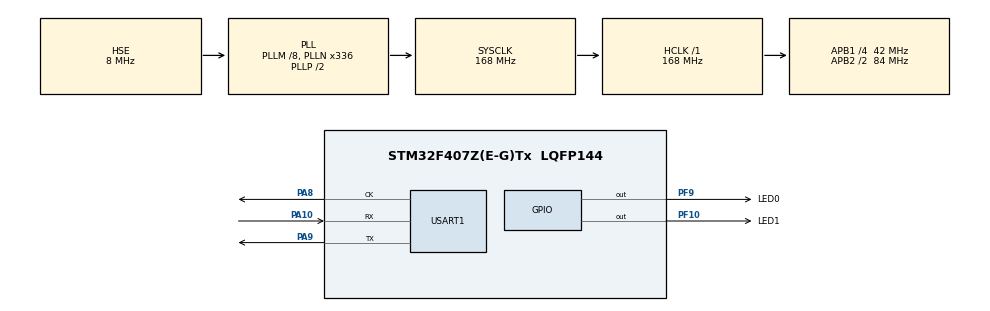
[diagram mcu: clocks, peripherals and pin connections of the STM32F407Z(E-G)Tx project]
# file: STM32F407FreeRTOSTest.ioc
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FREERTOS.Tasks01=LED0_Task,0,128,LED0,Default,NULL,Dynamic,NULL,NULL;LED1_Task,-3,128,LED1,Default,NULL,Dynamic,NULL,NULL
Mcu.Family=STM32F4
Mcu.Name=STM32F407Z(E-G)Tx
Mcu.Package=LQFP144
NVIC.PriorityGroup=NVIC_PRIORITYGROUP_4
NVIC.TIM6_DAC_IRQn=true\:15\:0\:false\:false\:true\:false\:false\:true
NVIC.TimeBase=TIM6_DAC_IRQn
NVIC.TimeBaseIP=TIM6
NVIC.USART1_IRQn=true\:5\:0\:false\:false\:true\:true\:true\:true
PA10.Mode=Synchronous
PA10.Signal=USART1_RX
PA13.Mode=Serial_Wire
PA13.Signal=SYS_JTMS-SWDIO
PA14.Mode=Serial_Wire
PA14.Signal=SYS_JTCK-SWCLK
PA8.Mode=Synchronous
PA8.Signal=USART1_CK
PA9.Mode=Synchronous
PA9.Signal=USART1_TX
PC14-OSC32_IN.Mode=LSE-External-Oscillator
PC14-OSC32_IN.Signal=RCC_OSC32_IN
PC15-OSC32_OUT.Mode=LSE-External-Oscillator
PC15-OSC32_OUT.Signal=RCC_OSC32_OUT
PF10.GPIO_Label=LED1
PF10.GPIO_Speed=GPIO_SPEED_FREQ_LOW
PF10.Signal=GPIO_Output
PF9.GPIO_Label=LED0
PF9.GPIO_Speed=GPIO_SPEED_FREQ_LOW
PF9.Signal=GPIO_Output
PH0-OSC_IN.Mode=HSE-External-Oscillator
PH0-OSC_IN.Signal=RCC_OSC_IN
PH1-OSC_OUT.Mode=HSE-External-Oscillator
PH1-OSC_OUT.Signal=RCC_OSC_OUT
ProjectManager.HeapSize=0x200
ProjectManager.StackSize=0x400
ProjectManager.TargetToolchain=MDK-ARM V5.32
RCC.48MHZClocksFreq_Value=84000000
RCC.AHBFreq_Value=168000000
RCC.APB1CLKDivider=RCC_HCLK_DIV4
RCC.APB1Freq_Value=42000000
RCC.APB1TimFreq_Value=84000000
RCC.APB2CLKDivider=RCC_HCLK_DIV2
RCC.APB2Freq_Value=84000000
RCC.APB2TimFreq_Value=168000000
RCC.CortexFreq_Value=168000000
RCC.EnbaleCSS=true
RCC.HCLKFreq_Value=168000000
RCC.HSE_VALUE=8000000
RCC.HSI_VALUE=16000000
RCC.PLLM=8
RCC.PLLN=336
RCC.PLLSourceVirtual=RCC_PLLSOURCE_HSE
RCC.SYSCLKFreq_VALUE=168000000
RCC.SYSCLKSource=RCC_SYSCLKSOURCE_PLLCLK
RCC.VCOOutputFreq_Value=336000000
USART1.VirtualMode=VM_SYNC
VP_FREERTOS_VS_CMSIS_V1.Mode=CMSIS_V1
VP_SYS_VS_tim6.Mode=TIM6
board=custom

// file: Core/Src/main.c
/* USER CODE BEGIN Header */
/**
  ******************************************************************************
  * @file           : main.c
  * @brief          : Main program body
  ******************************************************************************
  * @attention
  *
  * <h2><center>&copy; Copyright (c) 2025 STMicroelectronics.
  * All rights reserved.</center></h2>
  *
  * This software component is licensed by ST under Ultimate Liberty license
  * SLA0044, the "License"; You may not use this file except in compliance with
  * the License. You may obtain a copy of the License at:
  *                             www.st.com/SLA0044
  *
  ******************************************************************************
  */
/* USER CODE END Header */
#include "main.h"
#include "cmsis_os.h"

/* USER CODE BEGIN Includes */
#include "delay.h"
/* USER CODE END Includes */

USART_HandleTypeDef husart1;

osThreadId LED0_TaskHandle;
osThreadId LED1_TaskHandle;

void SystemClock_Config(void);
static void MX_GPIO_Init(void);
static void MX_USART1_Init(void);
void LED0(void const * argument);
void LED1(void const * argument);

int main(void)
{

  /* MCU Configuration--------------------------------------------------------*/

  /* Reset of all peripherals, Initializes the Flash interface and the Systick. */
  HAL_Init();

  /* Configure the system clock */
  SystemClock_Config();

  /* Initialize all configured peripherals */
  MX_GPIO_Init();
  MX_USART1_Init();

  /* Create the thread(s) */
  /* definition and creation of LED0_Task */
  osThreadDef(LED0_Task, LED0, osPriorityNormal, 0, 128);
  LED0_TaskHandle = osThreadCreate(osThread(LED0_Task), NULL);

  /* definition and creation of LED1_Task */
  osThreadDef(LED1_Task, LED1, osPriorityIdle, 0, 128);
  LED1_TaskHandle = osThreadCreate(osThread(LED1_Task), NULL);

  /* Start scheduler */
  osKernelStart();

  /* We should never get here as control is now taken by the scheduler */
  /* Infinite loop */
  while (1)
  {

  }
}

void SystemClock_Config(void)
{
  RCC_OscInitTypeDef RCC_OscInitStruct = {0};
  RCC_ClkInitTypeDef RCC_ClkInitStruct = {0};

  /** Configure the main internal regulator output voltage
  */
  __HAL_RCC_PWR_CLK_ENABLE();
  __HAL_PWR_VOLTAGESCALING_CONFIG(PWR_REGULATOR_VOLTAGE_SCALE1);
  /** Initializes the RCC Oscillators according to the specified parameters
  * in the RCC_OscInitTypeDef structure.
  */
  RCC_OscInitStruct.OscillatorType = RCC_OSCILLATORTYPE_HSE;
  RCC_OscInitStruct.HSEState = RCC_HSE_ON;
  RCC_OscInitStruct.PLL.PLLState = RCC_PLL_ON;
  RCC_OscInitStruct.PLL.PLLSource = RCC_PLLSOURCE_HSE;
  RCC_OscInitStruct.PLL.PLLM = 8;
  RCC_OscInitStruct.PLL.PLLN = 336;
  RCC_OscInitStruct.PLL.PLLP = RCC_PLLP_DIV2;
  RCC_OscInitStruct.PLL.PLLQ = 4;
  if (HAL_RCC_OscConfig(&RCC_OscInitStruct) != HAL_OK)
  {
    Error_Handler();
  }
  /** Initializes the CPU, AHB and APB buses clocks
  */
  RCC_ClkInitStruct.ClockType = RCC_CLOCKTYPE_HCLK|RCC_CLOCKTYPE_SYSCLK
                              |RCC_CLOCKTYPE_PCLK1|RCC_CLOCKTYPE_PCLK2;
  RCC_ClkInitStruct.SYSCLKSource = RCC_SYSCLKSOURCE_PLLCLK;
  RCC_ClkInitStruct.AHBCLKDivider = RCC_SYSCLK_DIV1;
  RCC_ClkInitStruct.APB1CLKDivider = RCC_HCLK_DIV4;
  RCC_ClkInitStruct.APB2CLKDivider = RCC_HCLK_DIV2;

  if (HAL_RCC_ClockConfig(&RCC_ClkInitStruct, FLASH_LATENCY_5) != HAL_OK)
  {
    Error_Handler();
  }
  /** Enables the Clock Security System
  */
  HAL_RCC_EnableCSS();
}

static void MX_USART1_Init(void)
{

  husart1.Instance = USART1;
  husart1.Init.BaudRate = 115200;
  husart1.Init.WordLength = USART_WORDLENGTH_8B;
  husart1.Init.StopBits = USART_STOPBITS_1;
  husart1.Init.Parity = USART_PARITY_NONE;
  husart1.Init.Mode = USART_MODE_TX_RX;
  husart1.Init.CLKPolarity = USART_POLARITY_LOW;
  husart1.Init.CLKPhase = USART_PHASE_1EDGE;
  husart1.Init.CLKLastBit = USART_LASTBIT_DISABLE;
  if (HAL_USART_Init(&husart1) != HAL_OK)
  {
    Error_Handler();
  }

}

static void MX_GPIO_Init(void)
{
  GPIO_InitTypeDef GPIO_InitStruct = {0};

  /* GPIO Ports Clock Enable */
  __HAL_RCC_GPIOC_CLK_ENABLE();
  __HAL_RCC_GPIOF_CLK_ENABLE();
  __HAL_RCC_GPIOH_CLK_ENABLE();
  __HAL_RCC_GPIOA_CLK_ENABLE();

  /*Configure GPIO pin Output Level */
  HAL_GPIO_WritePin(GPIOF, LED0_Pin|LED1_Pin, GPIO_PIN_RESET);

  /*Configure GPIO pins : LED0_Pin LED1_Pin */
  GPIO_InitStruct.Pin = LED0_Pin|LED1_Pin;
  GPIO_InitStruct.Mode = GPIO_MODE_OUTPUT_PP;
  GPIO_InitStruct.Pull = GPIO_NOPULL;
  GPIO_InitStruct.Speed = GPIO_SPEED_FREQ_LOW;
  HAL_GPIO_Init(GPIOF, &GPIO_InitStruct);

}

void LED0(void const * argument)
{
  /* USER CODE BEGIN 5 */
  /* Infinite loop */
  for(;;)
  {
		HAL_GPIO_TogglePin(LED0_GPIO_Port,LED0_Pin);
		HAL_Delay(500);
		//Delay.delay_us(500000);
		vTaskDelay(10);
//    osDelay(1);
  }
  /* USER CODE END 5 */
}

void LED1(void const * argument)
{
  /* USER CODE BEGIN LED1 */
  /* Infinite loop */
  for(;;)
  {
		HAL_GPIO_TogglePin(LED1_GPIO_Port,LED1_Pin);

		HAL_Delay(1000);
		//Delay.delay_us(500000);
		vTaskDelay(10);
//    osDelay(1);
  }
  /* USER CODE END LED1 */
}

void HAL_TIM_PeriodElapsedCallback(TIM_HandleTypeDef *htim)
{
  if (htim->Instance == TIM6) {
    HAL_IncTick();
  }
}

void Error_Handler(void)
{
  __disable_irq();
  while (1)
  {
  }
}

/************************ (C) COPYRIGHT STMicroelectronics *****END OF FILE****/
